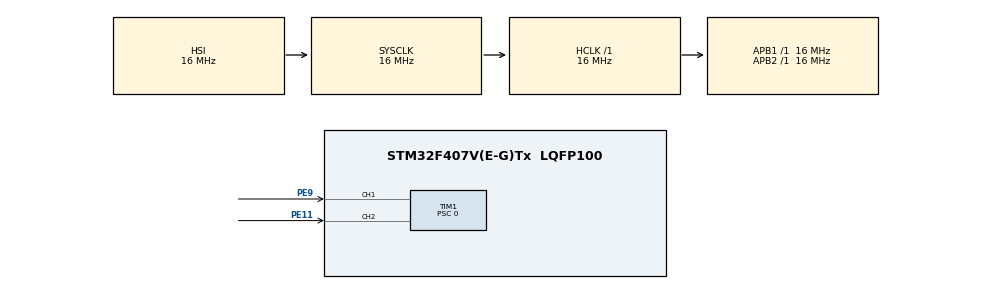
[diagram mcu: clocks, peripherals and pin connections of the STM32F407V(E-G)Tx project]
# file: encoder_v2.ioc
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Mcu.Family=STM32F4
Mcu.Name=STM32F407V(E-G)Tx
Mcu.Package=LQFP100
NVIC.PriorityGroup=NVIC_PRIORITYGROUP_4
PE11.GPIO_ModeDefaultPP=GPIO_MODE_AF_PP
PE11.GPIO_PuPd=GPIO_PULLUP
PE11.Signal=S_TIM1_CH2
PE9.GPIO_PuPd=GPIO_PULLUP
PE9.Signal=S_TIM1_CH1
ProjectManager.HeapSize=0x200
ProjectManager.StackSize=0x400
ProjectManager.TargetToolchain=MDK-ARM V5
RCC.AHBFreq_Value=16000000
RCC.APB1Freq_Value=16000000
RCC.APB2Freq_Value=16000000
RCC.CortexFreq_Value=16000000
RCC.HSE_VALUE=25000000
RCC.HSI_VALUE=16000000
RCC.LSE_VALUE=32768
RCC.SYSCLKFreq_VALUE=16000000
RCC.VCOOutputFreq_Value=192000000
SH.S_TIM1_CH1.0=TIM1_CH1,Encoder_Interface
SH.S_TIM1_CH2.0=TIM1_CH2,Encoder_Interface
TIM1.EncoderMode=TIM_ENCODERMODE_TI12
TIM1.IC1Filter=15
TIM1.IC2Filter=15
TIM1.Period=2400
TIM1.Prescaler=0
board=encoder_v2

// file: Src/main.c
/**
  ******************************************************************************
  * File Name          : main.c
  * Description        : Main program body
  ******************************************************************************
  ** This notice applies to any and all portions of this file
  * that are not between comment pairs USER CODE BEGIN and
  * USER CODE END. Other portions of this file, whether
  * inserted by the user or by software development tools
  * are owned by their respective copyright owners.
  *
  * COPYRIGHT(c) 2018 STMicroelectronics
  *
  * Redistribution and use in source and binary forms, with or without modification,
  * are permitted provided that the following conditions are met:
  *   1. Redistributions of source code must retain the above copyright notice,
  *      this list of conditions and the following disclaimer.
  *   2. Redistributions in binary form must reproduce the above copyright notice,
  *      this list of conditions and the following disclaimer in the documentation
  *      and/or other materials provided with the distribution.
  *   3. Neither the name of STMicroelectronics nor the names of its contributors
  *      may be used to endorse or promote products derived from this software
  *      without specific prior written permission.
  *
  * THIS SOFTWARE IS PROVIDED BY THE COPYRIGHT HOLDERS AND CONTRIBUTORS "AS IS"
  * AND ANY EXPRESS OR IMPLIED WARRANTIES, INCLUDING, BUT NOT LIMITED TO, THE
  * IMPLIED WARRANTIES OF MERCHANTABILITY AND FITNESS FOR A PARTICULAR PURPOSE ARE
  * DISCLAIMED. IN NO EVENT SHALL THE COPYRIGHT HOLDER OR CONTRIBUTORS BE LIABLE
  * FOR ANY DIRECT, INDIRECT, INCIDENTAL, SPECIAL, EXEMPLARY, OR CONSEQUENTIAL
  * DAMAGES (INCLUDING, BUT NOT LIMITED TO, PROCUREMENT OF SUBSTITUTE GOODS OR
  * SERVICES; LOSS OF USE, DATA, OR PROFITS; OR BUSINESS INTERRUPTION) HOWEVER
  * CAUSED AND ON ANY THEORY OF LIABILITY, WHETHER IN CONTRACT, STRICT LIABILITY,
  * OR TORT (INCLUDING NEGLIGENCE OR OTHERWISE) ARISING IN ANY WAY OUT OF THE USE
  * OF THIS SOFTWARE, EVEN IF ADVISED OF THE POSSIBILITY OF SUCH DAMAGE.
  *
  ******************************************************************************
  */
#include "main.h"
#include "stm32f4xx_hal.h"

TIM_HandleTypeDef htim1;

/* USER CODE BEGIN PV */
/* Private variables ---------------------------------------------------------*/

/* USER CODE END PV */

void SystemClock_Config(void);
static void MX_GPIO_Init(void);
static void MX_TIM1_Init(void);

/* USER CODE BEGIN PFP */
/* Private function prototypes -----------------------------------------------*/

/* USER CODE END PFP */

/* USER CODE BEGIN 0 */
uint16_t i;
float deg, temp_deg;
/* USER CODE END 0 */

int main(void)
{

  /* USER CODE BEGIN 1 */
	i = 0;
  /* USER CODE END 1 */

  /* MCU Configuration----------------------------------------------------------*/

  /* Reset of all peripherals, Initializes the Flash interface and the Systick. */
  HAL_Init();

  /* Configure the system clock */
  SystemClock_Config();

  /* Initialize all configured peripherals */
  MX_GPIO_Init();
  MX_TIM1_Init();

  /* USER CODE BEGIN 2 */
	HAL_TIM_Encoder_Start(&htim1,TIM_CHANNEL_ALL);

  /* USER CODE END 2 */

  /* Infinite loop */
  while (1)
  {
		i = TIM1->CNT;
		temp_deg = 360*i/2400;
		if(temp_deg > 90){
			deg = 360 - temp_deg;
		}else{
			deg = temp_deg * -1;
		}
  }

}

/** System Clock Configuration
*/
void SystemClock_Config(void)
{

  RCC_OscInitTypeDef RCC_OscInitStruct;
  RCC_ClkInitTypeDef RCC_ClkInitStruct;

    /**Configure the main internal regulator output voltage
    */
  __HAL_RCC_PWR_CLK_ENABLE();

  __HAL_PWR_VOLTAGESCALING_CONFIG(PWR_REGULATOR_VOLTAGE_SCALE1);

    /**Initializes the CPU, AHB and APB busses clocks
    */
  RCC_OscInitStruct.OscillatorType = RCC_OSCILLATORTYPE_HSI;
  RCC_OscInitStruct.HSIState = RCC_HSI_ON;
  RCC_OscInitStruct.HSICalibrationValue = 16;
  RCC_OscInitStruct.PLL.PLLState = RCC_PLL_NONE;
  if (HAL_RCC_OscConfig(&RCC_OscInitStruct) != HAL_OK)
  {
    _Error_Handler(__FILE__, __LINE__);
  }

    /**Initializes the CPU, AHB and APB busses clocks
    */
  RCC_ClkInitStruct.ClockType = RCC_CLOCKTYPE_HCLK|RCC_CLOCKTYPE_SYSCLK
                              |RCC_CLOCKTYPE_PCLK1|RCC_CLOCKTYPE_PCLK2;
  RCC_ClkInitStruct.SYSCLKSource = RCC_SYSCLKSOURCE_HSI;
  RCC_ClkInitStruct.AHBCLKDivider = RCC_SYSCLK_DIV1;
  RCC_ClkInitStruct.APB1CLKDivider = RCC_HCLK_DIV1;
  RCC_ClkInitStruct.APB2CLKDivider = RCC_HCLK_DIV1;

  if (HAL_RCC_ClockConfig(&RCC_ClkInitStruct, FLASH_LATENCY_0) != HAL_OK)
  {
    _Error_Handler(__FILE__, __LINE__);
  }

    /**Configure the Systick interrupt time
    */
  HAL_SYSTICK_Config(HAL_RCC_GetHCLKFreq()/1000);

    /**Configure the Systick
    */
  HAL_SYSTICK_CLKSourceConfig(SYSTICK_CLKSOURCE_HCLK);

  /* SysTick_IRQn interrupt configuration */
  HAL_NVIC_SetPriority(SysTick_IRQn, 0, 0);
}

/* TIM1 init function */
static void MX_TIM1_Init(void)
{

  TIM_Encoder_InitTypeDef sConfig;
  TIM_MasterConfigTypeDef sMasterConfig;

  htim1.Instance = TIM1;
  htim1.Init.Prescaler = 0;
  htim1.Init.CounterMode = TIM_COUNTERMODE_UP;
  htim1.Init.Period = 2400;
  htim1.Init.ClockDivision = TIM_CLOCKDIVISION_DIV1;
  htim1.Init.RepetitionCounter = 0;
  sConfig.EncoderMode = TIM_ENCODERMODE_TI12;
  sConfig.IC1Polarity = TIM_ICPOLARITY_RISING;
  sConfig.IC1Selection = TIM_ICSELECTION_DIRECTTI;
  sConfig.IC1Prescaler = TIM_ICPSC_DIV1;
  sConfig.IC1Filter = 15;
  sConfig.IC2Polarity = TIM_ICPOLARITY_RISING;
  sConfig.IC2Selection = TIM_ICSELECTION_DIRECTTI;
  sConfig.IC2Prescaler = TIM_ICPSC_DIV1;
  sConfig.IC2Filter = 15;
  if (HAL_TIM_Encoder_Init(&htim1, &sConfig) != HAL_OK)
  {
    _Error_Handler(__FILE__, __LINE__);
  }

  sMasterConfig.MasterOutputTrigger = TIM_TRGO_RESET;
  sMasterConfig.MasterSlaveMode = TIM_MASTERSLAVEMODE_DISABLE;
  if (HAL_TIMEx_MasterConfigSynchronization(&htim1, &sMasterConfig) != HAL_OK)
  {
    _Error_Handler(__FILE__, __LINE__);
  }

}

/** Pinout Configuration
*/
static void MX_GPIO_Init(void)
{

  /* GPIO Ports Clock Enable */
  __HAL_RCC_GPIOE_CLK_ENABLE();

}

void _Error_Handler(char * file, int line)
{
  while(1)
  {
  }
}

/************************ (C) COPYRIGHT STMicroelectronics *****END OF FILE****/
